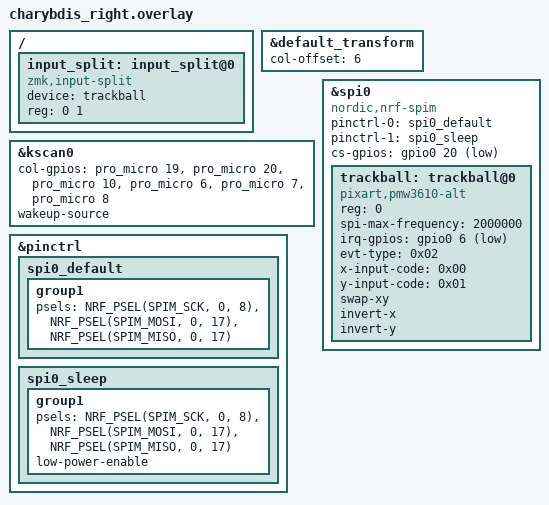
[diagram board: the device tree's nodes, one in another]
/*
 * Copyright (c) 2020 ZMK Contributors
 *
 * SPDX-License-Identifier: MIT
 */

#include "charybdis.dtsi"

&default_transform {
    col-offset = <6>;
};

&kscan0 {
    col-gpios
        = <&pro_micro 19 (GPIO_ACTIVE_HIGH | GPIO_PULL_DOWN)>
        , <&pro_micro 20 (GPIO_ACTIVE_HIGH | GPIO_PULL_DOWN)>
        , <&pro_micro 10 (GPIO_ACTIVE_HIGH | GPIO_PULL_DOWN)>
        , <&pro_micro 6 (GPIO_ACTIVE_HIGH | GPIO_PULL_DOWN)>
        , <&pro_micro 7 (GPIO_ACTIVE_HIGH | GPIO_PULL_DOWN)>
        , <&pro_micro 8 (GPIO_ACTIVE_HIGH | GPIO_PULL_DOWN)>
        ;
        
        wakeup-source;
};

// trackball bus
&pinctrl {
    spi0_default: spi0_default {
        group1 {
            psels = <NRF_PSEL(SPIM_SCK, 0, 8)>,
                <NRF_PSEL(SPIM_MOSI, 0, 17)>,
                <NRF_PSEL(SPIM_MISO, 0, 17)>;
        };
    };

    spi0_sleep: spi0_sleep {
        group1 {
            psels = <NRF_PSEL(SPIM_SCK, 0, 8)>,
                <NRF_PSEL(SPIM_MOSI, 0, 17)>,
                <NRF_PSEL(SPIM_MISO, 0, 17)>;
            low-power-enable;
        };
    };
};

&spi0 {
    status = "okay";
    compatible = "nordic,nrf-spim";
    pinctrl-0 = <&spi0_default>;
    pinctrl-1 = <&spi0_sleep>;
    pinctrl-names = "default", "sleep";
    cs-gpios = <&gpio0 20 GPIO_ACTIVE_LOW>;

    trackball: trackball@0 {
        status = "okay";
        compatible = "pixart,pmw3610-alt";
        reg = <0>;
        spi-max-frequency = <2000000>;
        irq-gpios = <&gpio0 6 (GPIO_ACTIVE_LOW | GPIO_PULL_UP)>;

        /* Event Configuration Requirements */
        evt-type = <0x02>;   /* INPUT_EV_REL */
        x-input-code = <0x00>;   /* INPUT_REL_X */
        y-input-code = <0x01>;   /* INPUT_REL_Y */

        /* Native sensor orientation transformations */
        swap-xy; 
        invert-x;
        invert-y;
    };
};

/* ── NATIVE WIRELESS FORWARDING PIPELINE ── */
/ {
    input_split: input_split@0 {
        compatible = "zmk,input-split";
        status = "okay";
        device = <&trackball>;
        reg = <0 1>;  /* address 0, size 1 */
    };
};
